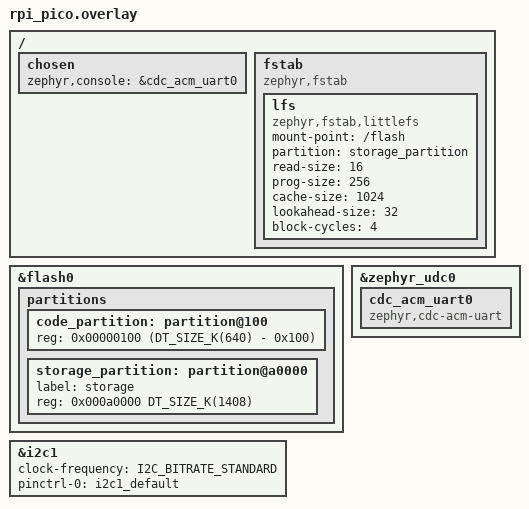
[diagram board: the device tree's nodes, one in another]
/*
 * Copyright (c) 2025 Damien P. George
 *
 * SPDX-License-Identifier: Apache-2.0
 */

/ {
	chosen {
		/* Use USB CDC ACM as the console. */
		zephyr,console = &cdc_acm_uart0;
	};

	fstab {
		compatible = "zephyr,fstab";
		lfs: lfs {
			compatible = "zephyr,fstab,littlefs";
			mount-point = "/flash";
			partition = <&storage_partition>;
			read-size=<16>;
			prog-size=<256>;
			cache-size=<1024>;
			lookahead-size=<32>;
			block-cycles=<4>;
		};
	};
};

&flash0 {
	partitions {
		code_partition: partition@100 {
			reg = <0x00000100 (DT_SIZE_K(640) - 0x100)>;
		};

		/* Storage slot: 1408 KiB placed after code_partition. */
		storage_partition: partition@a0000 {
			label = "storage";
			reg = <0x000a0000 DT_SIZE_K(1408)>;
		};
	};
};

&zephyr_udc0 {
	cdc_acm_uart0: cdc_acm_uart0 {
		compatible = "zephyr,cdc-acm-uart";
	};
};

&i2c1 {
	clock-frequency = <I2C_BITRATE_STANDARD>;
	status = "okay";
	pinctrl-0 = <&i2c1_default>;
	pinctrl-names = "default";
};
